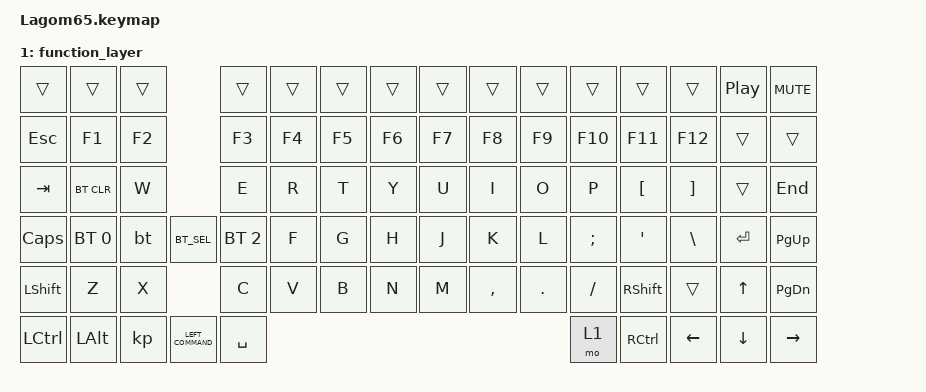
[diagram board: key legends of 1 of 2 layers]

#include <behaviors.dtsi>
#include <dt-bindings/zmk/keys.h>
#include <dt-bindings/zmk/bt.h>

/ {
    keymap {
        compatible = "zmk,keymap";

        default_layer {

            bindings = <
    &trans      &trans       &trans              &trans      &trans      &trans      &trans      &trans      &trans      &trans      &trans      &trans      &trans        &kp C_PLAY_PAUSE    &kp C_MUTE 
    &kp ESC     &kp N1       &kp N2              &kp N3      &kp N4      &kp N5      &kp N6      &kp N7      &kp N8      &kp N9      &kp N0      &kp MINUS   &kp EQUAL     &kp BSPC            &kp HOME
    &kp TAB     &kp Q        &kp W               &kp E       &kp R       &kp T       &kp Y       &kp U       &kp I       &kp O       &kp P       &kp LBKT    &kp RBKT      &trans              &kp END
    &kp CAPS    &kp A        &kp S               &kp D       &kp F       &kp G       &kp H       &kp J       &kp K       &kp L       &kp SEMI    &kp SQT     &kp BSLH      &kp ENTER           &kp PG_UP
    &kp LSHFT   &kp Z        &kp X               &kp C       &kp V       &kp B       &kp N       &kp M       &kp COMMA   &kp DOT     &kp SLASH   &kp RSHFT   &trans        &kp UP              &kp PG_DN
    &kp LCTRL   &kp LALT     $kp LEFT_COMMAND                            &kp SPACE                                       &mo 1       &kp RCTRL                &kp LEFT     &kp DOWN            &kp RIGHT
    
            >;

            sensor-bindings = <&inc_dec_kp C_VOL_UP C_VOL_DN &inc_dec_kp PG_UP PG_DN>;
        };

        function_layer  {
            bindings = <
    &trans      &trans       &trans              &trans        &trans      &trans      &trans      &trans      &trans      &trans      &trans      &trans      &trans        &kp C_PLAY_PAUSE    &kp C_MUTE 
    &kp ESC     &kp F1       &kp F2              &kp F3        &kp F4      &kp F5      &kp F6      &kp F7      &kp F8      &kp F9      &kp F10     &kp F11     &kp F12       &trans              &trans
    &kp TAB     &bt BT_CLR   &kp W               &kp E         &kp R       &kp T       &kp Y       &kp U       &kp I       &kp O       &kp P       &kp LBKT    &kp RBKT      &trans              &kp END
    &kp CAPS    &bt BT_SEL 0 $bt BT_SEL 1        &bt BT_SEL 2  &kp F       &kp G       &kp H       &kp J       &kp K       &kp L       &kp SEMI    &kp SQT     &kp BSLH      &kp ENTER           &kp PG_UP
    &kp LSHFT   &kp Z        &kp X               &kp C         &kp V       &kp B       &kp N       &kp M       &kp COMMA   &kp DOT     &kp SLASH   &kp RSHFT   &trans        &kp UP              &kp PG_DN
    &kp LCTRL   &kp LALT     $kp LEFT_COMMAND                              &kp SPACE                                       &mo 1       &kp RCTRL               &kp LEFT     &kp DOWN             &kp RIGHT
    
            >;

        };
    };
};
